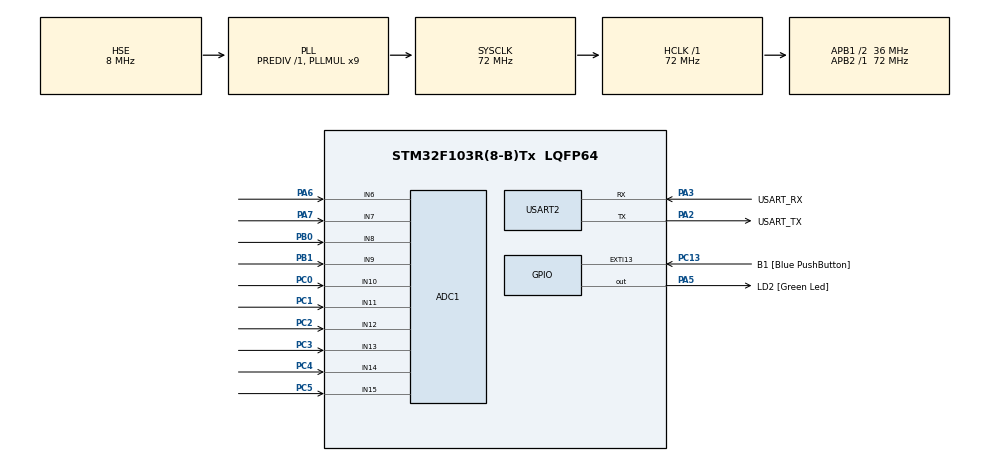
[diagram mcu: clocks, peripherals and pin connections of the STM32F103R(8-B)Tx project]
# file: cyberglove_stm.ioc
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ADC1.Channel-10\#ChannelRegularConversion=ADC_CHANNEL_11
ADC1.Channel-11\#ChannelRegularConversion=ADC_CHANNEL_12
ADC1.Channel-12\#ChannelRegularConversion=ADC_CHANNEL_13
ADC1.Channel-13\#ChannelRegularConversion=ADC_CHANNEL_14
ADC1.Channel-14\#ChannelRegularConversion=ADC_CHANNEL_15
ADC1.Channel-5\#ChannelRegularConversion=ADC_CHANNEL_6
ADC1.Channel-6\#ChannelRegularConversion=ADC_CHANNEL_7
ADC1.Channel-7\#ChannelRegularConversion=ADC_CHANNEL_8
ADC1.Channel-8\#ChannelRegularConversion=ADC_CHANNEL_9
ADC1.Channel-9\#ChannelRegularConversion=ADC_CHANNEL_10
ADC1.ContinuousConvMode=ENABLE
ADC1.EnableRegularConversion=ENABLE
ADC1.NbrOfConversion=10
ADC1.NbrOfConversionFlag=1
ADC1.Rank-10\#ChannelRegularConversion=6
ADC1.Rank-11\#ChannelRegularConversion=7
ADC1.Rank-12\#ChannelRegularConversion=8
ADC1.Rank-13\#ChannelRegularConversion=9
ADC1.Rank-14\#ChannelRegularConversion=10
ADC1.Rank-5\#ChannelRegularConversion=1
ADC1.Rank-6\#ChannelRegularConversion=2
ADC1.Rank-7\#ChannelRegularConversion=3
ADC1.Rank-8\#ChannelRegularConversion=4
ADC1.Rank-9\#ChannelRegularConversion=5
ADC1.SamplingTime-10\#ChannelRegularConversion=ADC_SAMPLETIME_71CYCLES_5
ADC1.SamplingTime-11\#ChannelRegularConversion=ADC_SAMPLETIME_71CYCLES_5
ADC1.SamplingTime-12\#ChannelRegularConversion=ADC_SAMPLETIME_71CYCLES_5
ADC1.SamplingTime-13\#ChannelRegularConversion=ADC_SAMPLETIME_71CYCLES_5
ADC1.SamplingTime-14\#ChannelRegularConversion=ADC_SAMPLETIME_71CYCLES_5
ADC1.SamplingTime-5\#ChannelRegularConversion=ADC_SAMPLETIME_71CYCLES_5
ADC1.SamplingTime-6\#ChannelRegularConversion=ADC_SAMPLETIME_71CYCLES_5
ADC1.SamplingTime-7\#ChannelRegularConversion=ADC_SAMPLETIME_71CYCLES_5
ADC1.SamplingTime-8\#ChannelRegularConversion=ADC_SAMPLETIME_71CYCLES_5
ADC1.SamplingTime-9\#ChannelRegularConversion=ADC_SAMPLETIME_71CYCLES_5
ADC1.master=1
Dma.ADC1.2.Direction=DMA_PERIPH_TO_MEMORY
Dma.ADC1.2.Instance=DMA1_Channel1
Dma.ADC1.2.MemDataAlignment=DMA_MDATAALIGN_WORD
Dma.ADC1.2.MemInc=DMA_MINC_ENABLE
Dma.ADC1.2.Mode=DMA_CIRCULAR
Dma.ADC1.2.PeriphDataAlignment=DMA_PDATAALIGN_WORD
Dma.ADC1.2.PeriphInc=DMA_PINC_DISABLE
Dma.ADC1.2.Priority=DMA_PRIORITY_LOW
Dma.Request0=USART2_RX
Dma.Request1=USART2_TX
Dma.Request2=ADC1
Dma.USART2_RX.0.Direction=DMA_PERIPH_TO_MEMORY
Dma.USART2_RX.0.Instance=DMA1_Channel6
Dma.USART2_RX.0.MemDataAlignment=DMA_MDATAALIGN_BYTE
Dma.USART2_RX.0.MemInc=DMA_MINC_ENABLE
Dma.USART2_RX.0.Mode=DMA_CIRCULAR
Dma.USART2_RX.0.PeriphDataAlignment=DMA_PDATAALIGN_BYTE
Dma.USART2_RX.0.PeriphInc=DMA_PINC_DISABLE
Dma.USART2_RX.0.Priority=DMA_PRIORITY_LOW
Dma.USART2_TX.1.Direction=DMA_MEMORY_TO_PERIPH
Dma.USART2_TX.1.Instance=DMA1_Channel7
Dma.USART2_TX.1.MemDataAlignment=DMA_MDATAALIGN_BYTE
Dma.USART2_TX.1.MemInc=DMA_MINC_ENABLE
Dma.USART2_TX.1.Mode=DMA_NORMAL
Dma.USART2_TX.1.PeriphDataAlignment=DMA_PDATAALIGN_BYTE
Dma.USART2_TX.1.PeriphInc=DMA_PINC_DISABLE
Dma.USART2_TX.1.Priority=DMA_PRIORITY_LOW
Mcu.Family=STM32F1
Mcu.Name=STM32F103R(8-B)Tx
Mcu.Package=LQFP64
NVIC.ADC1_2_IRQn=true\:0\:0\:false\:false\:true\:true
NVIC.DMA1_Channel1_IRQn=true\:0\:0\:false\:false\:true\:false
NVIC.DMA1_Channel6_IRQn=true\:0\:0\:false\:false\:true\:false
NVIC.DMA1_Channel7_IRQn=true\:0\:0\:false\:false\:true\:false
NVIC.EXTI15_10_IRQn=true\:0\:0\:false\:false\:true\:true
NVIC.PriorityGroup=NVIC_PRIORITYGROUP_4
NVIC.USART2_IRQn=true\:0\:0\:false\:false\:true\:true
PA13.GPIO_Label=TMS
PA13.Mode=Trace_Asynchronous_SW
PA13.Signal=SYS_JTMS-SWDIO
PA14.GPIO_Label=TCK
PA14.Mode=Trace_Asynchronous_SW
PA14.Signal=SYS_JTCK-SWCLK
PA2.GPIO_Label=USART_TX
PA2.GPIO_Mode=GPIO_MODE_AF_PP
PA2.GPIO_PuPd=GPIO_NOPULL
PA2.GPIO_Speed=GPIO_SPEED_FREQ_LOW
PA2.Mode=Asynchronous
PA2.Signal=USART2_TX
PA3.GPIO_Label=USART_RX
PA3.GPIO_Mode=GPIO_MODE_AF_PP
PA3.GPIO_PuPd=GPIO_NOPULL
PA3.GPIO_Speed=GPIO_SPEED_FREQ_LOW
PA3.Mode=Asynchronous
PA3.Signal=USART2_RX
PA5.GPIO_Label=LD2 [Green Led]
PA5.GPIO_ModeDefaultOutputPP=GPIO_MODE_OUTPUT_PP
PA5.GPIO_PuPd=GPIO_NOPULL
PA5.GPIO_Speed=GPIO_SPEED_FREQ_LOW
PA5.Signal=GPIO_Output
PA6.Signal=ADCx_IN6
PA7.Signal=ADCx_IN7
PB0.Signal=ADCx_IN8
PB1.Signal=ADCx_IN9
PB3.GPIO_Label=SWO
PB3.Mode=Trace_Asynchronous_SW
PB3.Signal=SYS_JTDO-TRACESWO
PC0.Signal=ADCx_IN10
PC1.Signal=ADCx_IN11
PC13-TAMPER-RTC.GPIO_Label=B1 [Blue PushButton]
PC13-TAMPER-RTC.GPIO_PuPd=GPIO_NOPULL
PC13-TAMPER-RTC.Signal=GPXTI13
PC14-OSC32_IN.Mode=LSE-External-Oscillator
PC14-OSC32_IN.Signal=RCC_OSC32_IN
PC15-OSC32_OUT.Mode=LSE-External-Oscillator
PC15-OSC32_OUT.Signal=RCC_OSC32_OUT
PC2.Signal=ADCx_IN12
PC3.Signal=ADCx_IN13
PC4.Signal=ADCx_IN14
PC5.Signal=ADCx_IN15
PD0-OSC_IN.Mode=HSE-External-Clock-Source
PD0-OSC_IN.Signal=RCC_OSC_IN
PD1-OSC_OUT.Mode=HSE-External-Clock-Source
PD1-OSC_OUT.Signal=RCC_OSC_OUT
ProjectManager.HeapSize=0x200
ProjectManager.StackSize=0x400
ProjectManager.TargetToolchain=TrueSTUDIO
RCC.ADCPresc=RCC_ADCPCLK2_DIV6
RCC.AHBFreq_Value=72000000
RCC.APB1CLKDivider=RCC_HCLK_DIV2
RCC.APB1Freq_Value=36000000
RCC.APB1TimFreq_Value=72000000
RCC.APB2Freq_Value=72000000
RCC.APB2TimFreq_Value=72000000
RCC.HCLKFreq_Value=72000000
RCC.PLLMUL=RCC_PLL_MUL9
RCC.PLLSourceVirtual=RCC_PLLSOURCE_HSE
RCC.RTCClockSelection=RCC_RTCCLKSOURCE_LSE
RCC.SYSCLKFreq_VALUE=72000000
RCC.SYSCLKSource=RCC_SYSCLKSOURCE_PLLCLK
RCC.USBFreq_Value=72000000
SH.ADCx_IN10.0=ADC1_IN10,IN10
SH.ADCx_IN11.0=ADC1_IN11,IN11
SH.ADCx_IN12.0=ADC1_IN12,IN12
SH.ADCx_IN13.0=ADC1_IN13,IN13
SH.ADCx_IN14.0=ADC1_IN14,IN14
SH.ADCx_IN15.0=ADC1_IN15,IN15
SH.ADCx_IN6.0=ADC1_IN6,IN6
SH.ADCx_IN7.0=ADC1_IN7,IN7
SH.ADCx_IN8.0=ADC1_IN8,IN8
SH.ADCx_IN9.0=ADC1_IN9,IN9
USART2.VirtualMode=VM_ASYNC
board=NUCLEO-F103RB

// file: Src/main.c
/**
 ******************************************************************************
 * @file           : main.c
 * @brief          : Main program body
 ******************************************************************************
 ** This notice applies to any and all portions of this file
 * that are not between comment pairs USER CODE BEGIN and
 * USER CODE END. Other portions of this file, whether
 * inserted by the user or by software development tools
 * are owned by their respective copyright owners.
 *
 * COPYRIGHT(c) 2018 STMicroelectronics
 *
 * Redistribution and use in source and binary forms, with or without modification,
 * are permitted provided that the following conditions are met:
 *   1. Redistributions of source code must retain the above copyright notice,
 *      this list of conditions and the following disclaimer.
 *   2. Redistributions in binary form must reproduce the above copyright notice,
 *      this list of conditions and the following disclaimer in the documentation
 *      and/or other materials provided with the distribution.
 *   3. Neither the name of STMicroelectronics nor the names of its contributors
 *      may be used to endorse or promote products derived from this software
 *      without specific prior written permission.
 *
 * THIS SOFTWARE IS PROVIDED BY THE COPYRIGHT HOLDERS AND CONTRIBUTORS "AS IS"
 * AND ANY EXPRESS OR IMPLIED WARRANTIES, INCLUDING, BUT NOT LIMITED TO, THE
 * IMPLIED WARRANTIES OF MERCHANTABILITY AND FITNESS FOR A PARTICULAR PURPOSE ARE
 * DISCLAIMED. IN NO EVENT SHALL THE COPYRIGHT HOLDER OR CONTRIBUTORS BE LIABLE
 * FOR ANY DIRECT, INDIRECT, INCIDENTAL, SPECIAL, EXEMPLARY, OR CONSEQUENTIAL
 * DAMAGES (INCLUDING, BUT NOT LIMITED TO, PROCUREMENT OF SUBSTITUTE GOODS OR
 * SERVICES; LOSS OF USE, DATA, OR PROFITS; OR BUSINESS INTERRUPTION) HOWEVER
 * CAUSED AND ON ANY THEORY OF LIABILITY, WHETHER IN CONTRACT, STRICT LIABILITY,
 * OR TORT (INCLUDING NEGLIGENCE OR OTHERWISE) ARISING IN ANY WAY OUT OF THE USE
 * OF THIS SOFTWARE, EVEN IF ADVISED OF THE POSSIBILITY OF SUCH DAMAGE.
 *
 ******************************************************************************
 */
#include "main.h"
#include "stm32f1xx_hal.h"
#include "adc.h"
#include "dma.h"
#include "usart.h"
#include "gpio.h"

/* USER CODE BEGIN Includes */
#include <stdio.h>
#include <stdlib.h>
#include <time.h>
/* USER CODE END Includes */

/* USER CODE BEGIN PV */
const uint32_t sensors_count=10;
uint32_t adc_buff[10];

/* Private variables ---------------------------------------------------------*/

/* USER CODE END PV */

void SystemClock_Config(void);

/* USER CODE BEGIN PFP */
/* Private function prototypes -----------------------------------------------*/

/* USER CODE END PFP */

int main(void)
{

	/* MCU Configuration----------------------------------------------------------*/

	/* Reset of all peripherals, Initializes the Flash interface and the Systick. */
	HAL_Init();

	/* Configure the system clock */
	SystemClock_Config();

	/* Initialize all configured peripherals */
	MX_GPIO_Init();
	MX_DMA_Init();
	MX_USART2_UART_Init();
	MX_ADC1_Init();
	/* USER CODE BEGIN 2 */
	printf("Program zosta³ uruchomiony.\r\n");
	HAL_ADC_Start_DMA(&hadc1, adc_buff, sensors_count);
	HAL_ADC_Start_IT(&hadc1);
	/* USER CODE END 2 */

	/* Infinite loop */
	/* USER CODE BEGIN WHILE */
	while(1)
	{
		HAL_ADC_Start_IT(&hadc1);

		printf("%lu|%lu|%lu|%lu|%lu|%lu|%lu|%lu|%lu|%lu\r\n", adc_buff[0],
				adc_buff[1], adc_buff[2], adc_buff[3], adc_buff[4], adc_buff[5],
				adc_buff[6], adc_buff[7], adc_buff[8], adc_buff[9]);

		HAL_Delay(50);
		/* USER CODE END WHILE */

	}

}

void SystemClock_Config(void)
{

	RCC_OscInitTypeDef RCC_OscInitStruct;
	RCC_ClkInitTypeDef RCC_ClkInitStruct;
	RCC_PeriphCLKInitTypeDef PeriphClkInit;

	/**Initializes the CPU, AHB and APB busses clocks
	 */
	RCC_OscInitStruct.OscillatorType= RCC_OSCILLATORTYPE_HSE;
	RCC_OscInitStruct.HSEState= RCC_HSE_BYPASS;
	RCC_OscInitStruct.HSEPredivValue= RCC_HSE_PREDIV_DIV1;
	RCC_OscInitStruct.HSIState= RCC_HSI_ON;
	RCC_OscInitStruct.PLL.PLLState= RCC_PLL_ON;
	RCC_OscInitStruct.PLL.PLLSource= RCC_PLLSOURCE_HSE;
	RCC_OscInitStruct.PLL.PLLMUL= RCC_PLL_MUL9;
	if(HAL_RCC_OscConfig(&RCC_OscInitStruct) != HAL_OK)
	{
		_Error_Handler(__FILE__, __LINE__);
	}

	/**Initializes the CPU, AHB and APB busses clocks
	 */
	RCC_ClkInitStruct.ClockType= RCC_CLOCKTYPE_HCLK | RCC_CLOCKTYPE_SYSCLK
			| RCC_CLOCKTYPE_PCLK1 | RCC_CLOCKTYPE_PCLK2;
	RCC_ClkInitStruct.SYSCLKSource= RCC_SYSCLKSOURCE_PLLCLK;
	RCC_ClkInitStruct.AHBCLKDivider= RCC_SYSCLK_DIV1;
	RCC_ClkInitStruct.APB1CLKDivider= RCC_HCLK_DIV2;
	RCC_ClkInitStruct.APB2CLKDivider= RCC_HCLK_DIV1;

	if(HAL_RCC_ClockConfig(&RCC_ClkInitStruct, FLASH_LATENCY_2) != HAL_OK)
	{
		_Error_Handler(__FILE__, __LINE__);
	}

	PeriphClkInit.PeriphClockSelection= RCC_PERIPHCLK_ADC;
	PeriphClkInit.AdcClockSelection= RCC_ADCPCLK2_DIV6;
	if(HAL_RCCEx_PeriphCLKConfig(&PeriphClkInit) != HAL_OK)
	{
		_Error_Handler(__FILE__, __LINE__);
	}

	/**Configure the Systick interrupt time
	 */
	HAL_SYSTICK_Config(HAL_RCC_GetHCLKFreq() / 1000);

	/**Configure the Systick
	 */
	HAL_SYSTICK_CLKSourceConfig(SYSTICK_CLKSOURCE_HCLK);

	/* SysTick_IRQn interrupt configuration */
	HAL_NVIC_SetPriority(SysTick_IRQn, 0, 0);
}

void _Error_Handler(char *file, int line)
{
	while(1)
	{
	}
}

/************************ (C) COPYRIGHT STMicroelectronics *****END OF FILE****/
